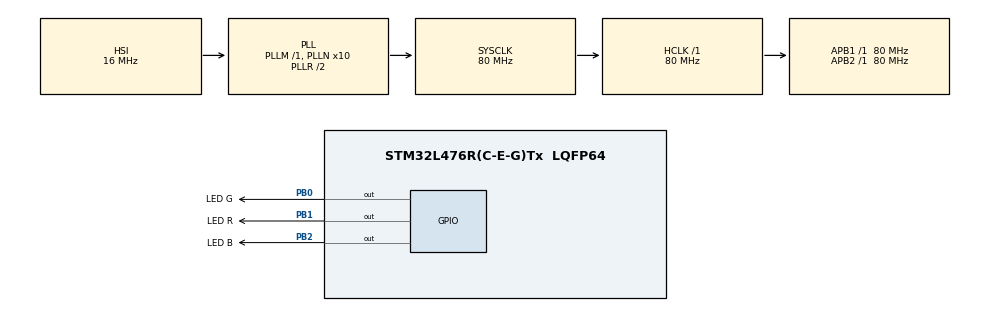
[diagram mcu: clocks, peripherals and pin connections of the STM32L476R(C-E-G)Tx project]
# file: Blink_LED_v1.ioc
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Mcu.Family=STM32L4
Mcu.Name=STM32L476R(C-E-G)Tx
Mcu.Package=LQFP64
NVIC.PriorityGroup=NVIC_PRIORITYGROUP_4
PA13\ (JTMS-SWDIO).Mode=Serial_Wire
PA13\ (JTMS-SWDIO).Signal=SYS_JTMS-SWDIO
PA14\ (JTCK-SWCLK).Mode=Serial_Wire
PA14\ (JTCK-SWCLK).Signal=SYS_JTCK-SWCLK
PB0.GPIO_Label=LED G
PB0.Signal=GPIO_Output
PB1.GPIO_Label=LED R
PB1.Signal=GPIO_Output
PB2.GPIO_Label=LED B
PB2.Signal=GPIO_Output
PH0-OSC_IN\ (PH0).Mode=HSE-External-Oscillator
PH0-OSC_IN\ (PH0).Signal=RCC_OSC_IN
PH1-OSC_OUT\ (PH1).Mode=HSE-External-Oscillator
PH1-OSC_OUT\ (PH1).Signal=RCC_OSC_OUT
ProjectManager.HeapSize=0x200
ProjectManager.StackSize=0x400
ProjectManager.TargetToolchain=MDK-ARM V5.32
RCC.ADCFreq_Value=64000000
RCC.AHBFreq_Value=80000000
RCC.APB1Freq_Value=80000000
RCC.APB1TimFreq_Value=80000000
RCC.APB2Freq_Value=80000000
RCC.APB2TimFreq_Value=80000000
RCC.CortexFreq_Value=80000000
RCC.HCLKFreq_Value=80000000
RCC.HSE_VALUE=16000000
RCC.HSI_VALUE=16000000
RCC.LSE_VALUE=32768
RCC.MSI_VALUE=4000000
RCC.PLLN=10
RCC.PLLSourceVirtual=RCC_PLLSOURCE_HSI
RCC.SYSCLKFreq_VALUE=80000000
RCC.SYSCLKSource=RCC_SYSCLKSOURCE_PLLCLK
RCC.USBFreq_Value=64000000
RCC.VCOOutputFreq_Value=160000000
board=custom

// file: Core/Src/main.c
/* USER CODE BEGIN Header */
/**
  ******************************************************************************
  * @file           : main.c
  * @brief          : Main program body
  ******************************************************************************
  * @attention
  *
  * Copyright (c) 2026 STMicroelectronics.
  * All rights reserved.
  *
  * This software is licensed under terms that can be found in the LICENSE file
  * in the root directory of this software component.
  * If no LICENSE file comes with this software, it is provided AS-IS.
  *
  ******************************************************************************
  */
/* USER CODE END Header */
#include "main.h"
#include "led_rgb.h"

/* USER CODE BEGIN Includes */
//#include <stdint.h>
/* USER CODE END Includes */

/* USER CODE BEGIN PV */
uint32_t test_time;
uint32_t last_time1 ;
uint32_t count = 0;

/* USER CODE END PV */

void SystemClock_Config(void);
static void MX_GPIO_Init(void);
/* USER CODE BEGIN PFP */

GPIO_TypeDef *port[] = {GPIOB, GPIOB, GPIOB};
uint16_t pin[] = {LED_R_Pin, LED_B_Pin, LED_G_Pin};

RGB mau;
/* USER CODE END PFP */

int main(void)
{

  /* MCU Configuration--------------------------------------------------------*/

  /* Reset of all peripherals, Initializes the Flash interface and the Systick. */
  HAL_Init();

  /* USER CODE BEGIN Init */
		rgb_init(&mau,port, pin);

  /* USER CODE END Init */

  /* Configure the system clock */
  SystemClock_Config();

  /* Initialize all configured peripherals */
  MX_GPIO_Init();
  /* USER CODE BEGIN 2 */
	uint32_t last_time = HAL_GetTick();
	 last_time1 = HAL_GetTick(); //1000

	static GPIO_PinState led_state = GPIO_PIN_RESET;

  /* USER CODE END 2 */

  /* Infinite loop */
  while (1)
  {
		rgb_blink(&mau,GREEN,1000);

		//rgb_blink(&rgb, WHITE, 500);

//		test_time = HAL_GetTick();
////			// cach 1
//			if (HAL_GetTick() - last_time1 >= 2000)
//			{
//					HAL_GPIO_TogglePin(GPIOB, LED_G_Pin);
//					last_time1 = HAL_GetTick();
////			}
////
//			if (HAL_GetTick() - last_time >= 100)
//			{
//					HAL_GPIO_TogglePin(GPIOB, LED_R_Pin);
//					last_time = HAL_GetTick();
		//	}
	//		HAL_GPIO_WritePin(GPIOB, LED_R_Pin, led_state);
			//HAL_GPIO_WritePin(rgb.GPIO_Red, rgb.red_pin, led_state);
			// cach 2
//			if (HAL_GetTick() - last_time >= 100)
//			{
//				led_state = (led_state == GPIO_PIN_SET) ? GPIO_PIN_RESET : GPIO_PIN_SET;
//
//				HAL_GPIO_WritePin(GPIOB, LED_R_Pin, led_state);
//				last_time = HAL_GetTick();
//			}
    /* USER CODE BEGIN 3 */
		//void HAL_GPIO_WritePin(GPIO_TypeDef* GPIOx, uint16_t GPIO_Pin, GPIO_PinState PinState)

  }
  /* USER CODE END 3 */
}

void SystemClock_Config(void)
{
  RCC_OscInitTypeDef RCC_OscInitStruct = {0};
  RCC_ClkInitTypeDef RCC_ClkInitStruct = {0};

  /** Configure the main internal regulator output voltage
  */
  if (HAL_PWREx_ControlVoltageScaling(PWR_REGULATOR_VOLTAGE_SCALE1) != HAL_OK)
  {
    Error_Handler();
  }

  /** Initializes the RCC Oscillators according to the specified parameters
  * in the RCC_OscInitTypeDef structure.
  */
  RCC_OscInitStruct.OscillatorType = RCC_OSCILLATORTYPE_HSI;
  RCC_OscInitStruct.HSIState = RCC_HSI_ON;
  RCC_OscInitStruct.HSICalibrationValue = RCC_HSICALIBRATION_DEFAULT;
  RCC_OscInitStruct.PLL.PLLState = RCC_PLL_ON;
  RCC_OscInitStruct.PLL.PLLSource = RCC_PLLSOURCE_HSI;
  RCC_OscInitStruct.PLL.PLLM = 1;
  RCC_OscInitStruct.PLL.PLLN = 10;
  RCC_OscInitStruct.PLL.PLLP = RCC_PLLP_DIV7;
  RCC_OscInitStruct.PLL.PLLQ = RCC_PLLQ_DIV2;
  RCC_OscInitStruct.PLL.PLLR = RCC_PLLR_DIV2;
  if (HAL_RCC_OscConfig(&RCC_OscInitStruct) != HAL_OK)
  {
    Error_Handler();
  }

  /** Initializes the CPU, AHB and APB buses clocks
  */
  RCC_ClkInitStruct.ClockType = RCC_CLOCKTYPE_HCLK|RCC_CLOCKTYPE_SYSCLK
                              |RCC_CLOCKTYPE_PCLK1|RCC_CLOCKTYPE_PCLK2;
  RCC_ClkInitStruct.SYSCLKSource = RCC_SYSCLKSOURCE_PLLCLK;
  RCC_ClkInitStruct.AHBCLKDivider = RCC_SYSCLK_DIV1;
  RCC_ClkInitStruct.APB1CLKDivider = RCC_HCLK_DIV1;
  RCC_ClkInitStruct.APB2CLKDivider = RCC_HCLK_DIV1;

  if (HAL_RCC_ClockConfig(&RCC_ClkInitStruct, FLASH_LATENCY_4) != HAL_OK)
  {
    Error_Handler();
  }
}

static void MX_GPIO_Init(void)
{
  GPIO_InitTypeDef GPIO_InitStruct = {0};

  /* GPIO Ports Clock Enable */
  __HAL_RCC_GPIOH_CLK_ENABLE();
  __HAL_RCC_GPIOB_CLK_ENABLE();
  __HAL_RCC_GPIOA_CLK_ENABLE();

  /*Configure GPIO pin Output Level */
  HAL_GPIO_WritePin(GPIOB, LED_G_Pin|LED_R_Pin|LED_B_Pin, GPIO_PIN_RESET);

  /*Configure GPIO pins : LED_G_Pin LED_R_Pin LED_B_Pin */
  GPIO_InitStruct.Pin = LED_G_Pin|LED_R_Pin|LED_B_Pin;
  GPIO_InitStruct.Mode = GPIO_MODE_OUTPUT_PP;
  GPIO_InitStruct.Pull = GPIO_NOPULL;
  GPIO_InitStruct.Speed = GPIO_SPEED_FREQ_LOW;
  HAL_GPIO_Init(GPIOB, &GPIO_InitStruct);

}

void Error_Handler(void)
{
  __disable_irq();
  while (1)
  {
  }
}
